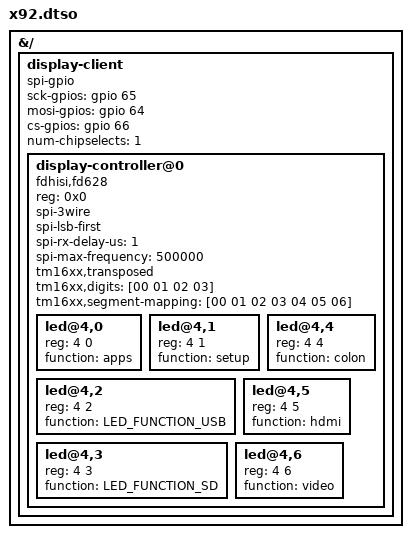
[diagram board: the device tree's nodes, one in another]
/dts-v1/;
/plugin/;

#include <dt-bindings/gpio/gpio.h>
#include <dt-bindings/leds/common.h>

&{/} {

	display-client {
		#address-cells = <1>;
		#size-cells = <0>;
		compatible = "spi-gpio";
		sck-gpios = <&gpio 65 0>;
		mosi-gpios = <&gpio 64 0>;
		cs-gpios = <&gpio 66 0>;
		num-chipselects = <1>;

		display-controller@0 {
			compatible = "fdhisi,fd628";
			reg = <0x0>;
			spi-3wire;
			spi-lsb-first;
			spi-rx-delay-us = <1>;
			spi-max-frequency = <500000>;

			tm16xx,transposed;
			tm16xx,digits = [00 01 02 03];
			tm16xx,segment-mapping = [00 01 02 03 04 05 06];

			#address-cells = <2>;
			#size-cells = <0>;
			
			led@4,0 {
				reg = <4 0>;
				function = "apps";
			};
			
			led@4,1 {
				reg = <4 1>;
				function = "setup";
			};
			
			led@4,2 {
				reg = <4 2>;
				function = LED_FUNCTION_USB;
			};
			
			led@4,3 {
				reg = <4 3>;
				function = LED_FUNCTION_SD;
			};
			
			led@4,4 {
				reg = <4 4>;
				function = "colon";
			};
			
			led@4,5 {
				reg = <4 5>;
				function = "hdmi";
			};
			
			led@4,6 {
				reg = <4 6>;
				function = "video";
			};

		};
	};
};
